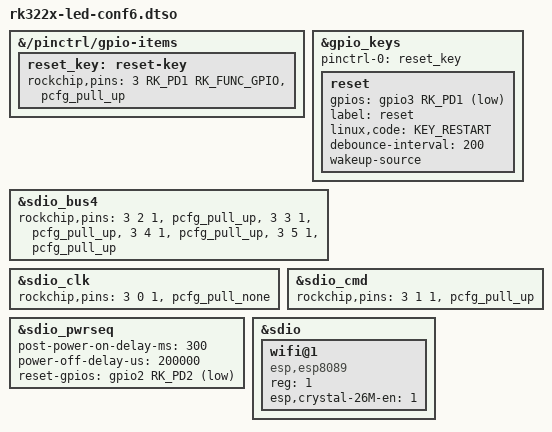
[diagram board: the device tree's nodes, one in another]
/dts-v1/;
/plugin/;

#include <dt-bindings/gpio/gpio.h>
#include <dt-bindings/input/input.h>
#include <dt-bindings/pinctrl/rockchip.h>

/*
 * gpio configuration for MXQ_PRO eMCP boards
 *
 * - fixes low strength on sdio pins for wifi
 * - correct gpio pins for wifi
 * - set emmc pins and default phase shift
 */

/ {

	fragment@0 {
		target-path = "/pinctrl/gpio-items";
		__overlay__ {

			reset_key: reset-key {
				rockchip,pins = <3 RK_PD1 RK_FUNC_GPIO &pcfg_pull_up>;
			};

		};
	};

	fragment@1 {
		target = <&gpio_keys>;
		__overlay__ {

			pinctrl-names = "default";
			pinctrl-0 = <&reset_key>;

			reset {
				gpios = <&gpio3 RK_PD1 GPIO_ACTIVE_LOW>;
				label = "reset";
				linux,code = <KEY_RESTART>;
				debounce-interval = <200>;
				wakeup-source;
			};
		
		};
	};

	fragment@2 {
		target = <&sdio_bus4>;
		__overlay__ {
			rockchip,pins = <3 2 1 &pcfg_pull_up>,
					<3 3 1 &pcfg_pull_up>,
					<3 4 1 &pcfg_pull_up>,
					<3 5 1 &pcfg_pull_up>;
		};

	};

	fragment@3 {
		target = <&sdio_clk>;
		__overlay__ {
			rockchip,pins = <3 0 1 &pcfg_pull_none>;
		};
	};

	fragment@4 {
		target = <&sdio_cmd>;
		__overlay__ {
			rockchip,pins = <3 1 1 &pcfg_pull_up>;
		};
	};

	fragment@5 {
		target = <&sdio_pwrseq>;
		__overlay__ {
			post-power-on-delay-ms = <300>;
			power-off-delay-us = <200000>;
			reset-gpios = <&gpio2 RK_PD2 GPIO_ACTIVE_LOW>;
		};
	};

	fragment@6 {
		target = <&sdio>;
		__overlay__ {
			#address-cells = <1>;
			#size-cells = <0>;

			wifi@1 {
				compatible = "esp,esp8089";
				reg = <1>;
				esp,crystal-26M-en = <1>;
			};

		};
	};

};
